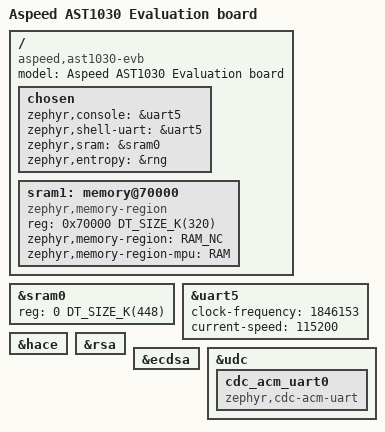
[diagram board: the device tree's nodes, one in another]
/*
 * Copyright (c) 2021 Aspeed Technology Inc.
 *
 * SPDX-License-Identifier: Apache-2.0
 */

/dts-v1/;
#include <aspeed/ast10x0.dtsi>

/ {
	model = "Aspeed AST1030 Evaluation board";
	compatible = "aspeed,ast1030-evb";

	chosen {
		zephyr,console = &uart5;
		zephyr,shell-uart = &uart5;
		zephyr,sram = &sram0;
		zephyr,entropy = &rng;
	};

	sram1: memory@70000 {
		compatible = "zephyr,memory-region", "mmio-sram";
		device_type = "memory";
		reg = <0x70000 DT_SIZE_K(320)>;
		zephyr,memory-region = "RAM_NC";
		zephyr,memory-region-mpu = "RAM";
	};
};

&sram0 {
	reg = <0 DT_SIZE_K(448)>;
};

&uart5 {
	clock-frequency = <1846153>;
	current-speed = <115200>;
	status = "okay";
};

&hace {
	status = "okay";
};

&rsa {
	status = "okay";
};

&ecdsa {
	status = "okay";
};

zephyr_udc0: &udc {
	status = "okay";
	cdc_acm_uart0: cdc_acm_uart0 {
		compatible = "zephyr,cdc-acm-uart";
	};
};
